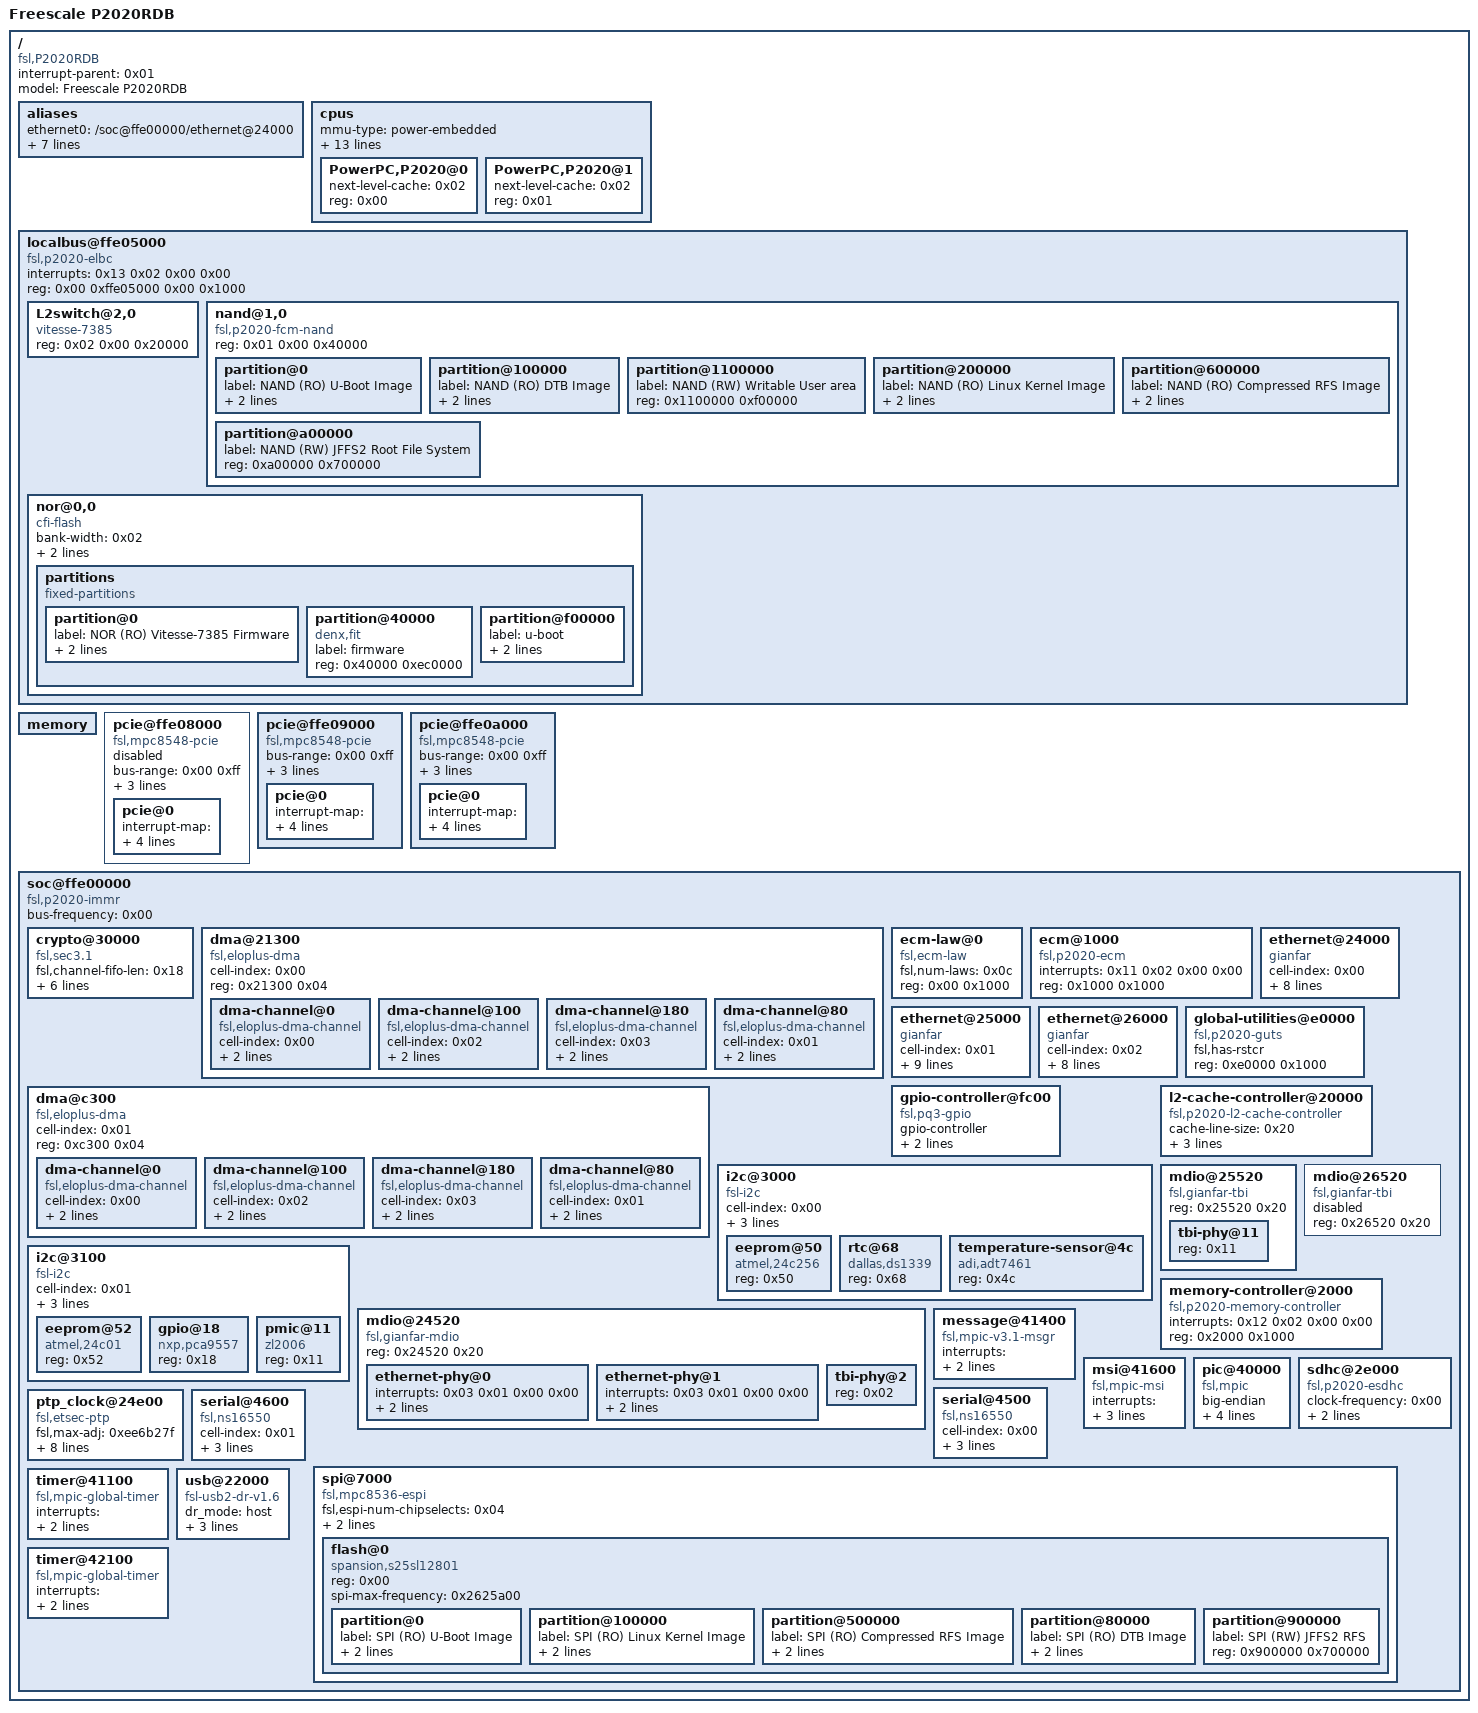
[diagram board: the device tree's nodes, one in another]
/dts-v1/;

/ {
	#address-cells = <0x02>;
	#size-cells = <0x02>;
	compatible = "fsl,P2020RDB";
	interrupt-parent = <0x01>;
	model = "Freescale P2020RDB";

	aliases {
		ethernet0 = "/soc@ffe00000/ethernet@24000";
		ethernet1 = "/soc@ffe00000/ethernet@25000";
		ethernet2 = "/soc@ffe00000/ethernet@26000";
		pci0 = "/pcie@ffe08000";
		pci1 = "/pcie@ffe09000";
		pci2 = "/pcie@ffe0a000";
		serial0 = "/soc@ffe00000/serial@4500";
		serial1 = "/soc@ffe00000/serial@4600";
	};

	cpus {
		#address-cells = <0x01>;
		#size-cells = <0x00>;
		mmu-type = "power-embedded";
		power-isa-atb;
		power-isa-b;
		power-isa-cs;
		power-isa-e;
		power-isa-e.le;
		power-isa-e.pm;
		power-isa-ecl;
		power-isa-mmc;
		power-isa-sp;
		power-isa-sp.fd;
		power-isa-sp.fs;
		power-isa-sp.fv;
		power-isa-version = "2.03";

		PowerPC,P2020@0 {
			device_type = "cpu";
			next-level-cache = <0x02>;
			reg = <0x00>;
		};

		PowerPC,P2020@1 {
			device_type = "cpu";
			next-level-cache = <0x02>;
			reg = <0x01>;
		};
	};

	localbus@ffe05000 {
		#address-cells = <0x02>;
		#size-cells = <0x01>;
		compatible = "fsl,p2020-elbc\0fsl,elbc\0simple-bus";
		interrupts = <0x13 0x02 0x00 0x00>;
		ranges = <0x00 0x00 0x00 0xef000000 0x1000000 0x01 0x00 0x00 0xffa00000 0x40000 0x02 0x00 0x00 0xffb00000 0x20000>;
		reg = <0x00 0xffe05000 0x00 0x1000>;

		L2switch@2,0 {
			#address-cells = <0x01>;
			#size-cells = <0x01>;
			compatible = "vitesse-7385";
			reg = <0x02 0x00 0x20000>;
		};

		nand@1,0 {
			#address-cells = <0x01>;
			#size-cells = <0x01>;
			compatible = "fsl,p2020-fcm-nand\0fsl,elbc-fcm-nand";
			reg = <0x01 0x00 0x40000>;

			partition@0 {
				label = "NAND (RO) U-Boot Image";
				read-only;
				reg = <0x00 0x100000>;
			};

			partition@100000 {
				label = "NAND (RO) DTB Image";
				read-only;
				reg = <0x100000 0x100000>;
			};

			partition@1100000 {
				label = "NAND (RW) Writable User area";
				reg = <0x1100000 0xf00000>;
			};

			partition@200000 {
				label = "NAND (RO) Linux Kernel Image";
				read-only;
				reg = <0x200000 0x400000>;
			};

			partition@600000 {
				label = "NAND (RO) Compressed RFS Image";
				read-only;
				reg = <0x600000 0x400000>;
			};

			partition@a00000 {
				label = "NAND (RW) JFFS2 Root File System";
				reg = <0xa00000 0x700000>;
			};
		};

		nor@0,0 {
			bank-width = <0x02>;
			compatible = "cfi-flash";
			device-width = <0x01>;
			reg = <0x00 0x00 0x1000000>;

			partitions {
				#address-cells = <0x01>;
				#size-cells = <0x01>;
				compatible = "fixed-partitions";

				partition@0 {
					label = "NOR (RO) Vitesse-7385 Firmware";
					read-only;
					reg = <0x00 0x40000>;
				};

				partition@40000 {
					compatible = "denx,fit";
					label = "firmware";
					reg = <0x40000 0xec0000>;
				};

				partition@f00000 {
					label = "u-boot";
					read-only;
					reg = <0xf00000 0x100000>;
				};
			};
		};
	};

	memory {
		device_type = "memory";
	};

	pcie@ffe08000 {
		#address-cells = <0x03>;
		#size-cells = <0x02>;
		bus-range = <0x00 0xff>;
		clock-frequency = <0x1fca055>;
		compatible = "fsl,mpc8548-pcie";
		device_type = "pci";
		interrupts = <0x1a 0x02 0x00 0x00>;
		reg = <0x00 0xffe08000 0x00 0x1000>;
		status = "disabled";

		pcie@0 {
			#address-cells = <0x03>;
			#interrupt-cells = <0x01>;
			#size-cells = <0x02>;
			device_type = "pci";
			interrupt-map = <0x00 0x00 0x00 0x01 0x01 0x00 0x01 0x00 0x00 0x00 0x00 0x00 0x02 0x01 0x01 0x01 0x00 0x00 0x00 0x00 0x00 0x03 0x01 0x02 0x01 0x00 0x00 0x00 0x00 0x00 0x04 0x01 0x03 0x01 0x00 0x00>;
			interrupt-map-mask = <0xf800 0x00 0x00 0x07>;
			interrupts = <0x1a 0x02 0x00 0x00>;
			reg = <0x00 0x00 0x00 0x00 0x00>;
		};
	};

	pcie@ffe09000 {
		#address-cells = <0x03>;
		#size-cells = <0x02>;
		bus-range = <0x00 0xff>;
		clock-frequency = <0x1fca055>;
		compatible = "fsl,mpc8548-pcie";
		device_type = "pci";
		interrupts = <0x19 0x02 0x00 0x00>;
		ranges = <0x2000000 0x00 0xa0000000 0x00 0xa0000000 0x00 0x20000000 0x1000000 0x00 0x00 0x00 0xffc10000 0x00 0x10000>;
		reg = <0x00 0xffe09000 0x00 0x1000>;

		pcie@0 {
			#address-cells = <0x03>;
			#interrupt-cells = <0x01>;
			#size-cells = <0x02>;
			device_type = "pci";
			interrupt-map = <0x00 0x00 0x00 0x01 0x01 0x04 0x01 0x00 0x00 0x00 0x00 0x00 0x02 0x01 0x05 0x01 0x00 0x00 0x00 0x00 0x00 0x03 0x01 0x06 0x01 0x00 0x00 0x00 0x00 0x00 0x04 0x01 0x07 0x01 0x00 0x00>;
			interrupt-map-mask = <0xf800 0x00 0x00 0x07>;
			interrupts = <0x19 0x02 0x00 0x00>;
			ranges = <0x2000000 0x00 0xa0000000 0x2000000 0x00 0xa0000000 0x00 0x20000000 0x1000000 0x00 0x00 0x1000000 0x00 0x00 0x00 0x100000>;
			reg = <0x00 0x00 0x00 0x00 0x00>;
		};
	};

	pcie@ffe0a000 {
		#address-cells = <0x03>;
		#size-cells = <0x02>;
		bus-range = <0x00 0xff>;
		clock-frequency = <0x1fca055>;
		compatible = "fsl,mpc8548-pcie";
		device_type = "pci";
		interrupts = <0x18 0x02 0x00 0x00>;
		ranges = <0x2000000 0x00 0x80000000 0x00 0x80000000 0x00 0x20000000 0x1000000 0x00 0x00 0x00 0xffc00000 0x00 0x10000>;
		reg = <0x00 0xffe0a000 0x00 0x1000>;

		pcie@0 {
			#address-cells = <0x03>;
			#interrupt-cells = <0x01>;
			#size-cells = <0x02>;
			device_type = "pci";
			interrupt-map = <0x00 0x00 0x00 0x01 0x01 0x08 0x01 0x00 0x00 0x00 0x00 0x00 0x02 0x01 0x09 0x01 0x00 0x00 0x00 0x00 0x00 0x03 0x01 0x0a 0x01 0x00 0x00 0x00 0x00 0x00 0x04 0x01 0x0b 0x01 0x00 0x00>;
			interrupt-map-mask = <0xf800 0x00 0x00 0x07>;
			interrupts = <0x18 0x02 0x00 0x00>;
			ranges = <0x2000000 0x00 0x80000000 0x2000000 0x00 0x80000000 0x00 0x20000000 0x1000000 0x00 0x00 0x1000000 0x00 0x00 0x00 0x100000>;
			reg = <0x00 0x00 0x00 0x00 0x00>;
		};
	};

	soc@ffe00000 {
		#address-cells = <0x01>;
		#size-cells = <0x01>;
		bus-frequency = <0x00>;
		compatible = "fsl,p2020-immr\0simple-bus";
		device_type = "soc";
		ranges = <0x00 0x00 0xffe00000 0x100000>;

		crypto@30000 {
			compatible = "fsl,sec3.1\0fsl,sec3.0\0fsl,sec2.4\0fsl,sec2.2\0fsl,sec2.1\0fsl,sec2.0";
			fsl,channel-fifo-len = <0x18>;
			fsl,descriptor-types-mask = <0x3ab0ebf>;
			fsl,exec-units-mask = <0xbfe>;
			fsl,num-channels = <0x04>;
			interrupts = <0x2d 0x02 0x00 0x00 0x3a 0x02 0x00 0x00>;
			reg = <0x30000 0x10000>;
		};

		dma@21300 {
			#address-cells = <0x01>;
			#size-cells = <0x01>;
			cell-index = <0x00>;
			compatible = "fsl,eloplus-dma";
			ranges = <0x00 0x21100 0x200>;
			reg = <0x21300 0x04>;

			dma-channel@0 {
				cell-index = <0x00>;
				compatible = "fsl,eloplus-dma-channel";
				interrupts = <0x14 0x02 0x00 0x00>;
				reg = <0x00 0x80>;
			};

			dma-channel@100 {
				cell-index = <0x02>;
				compatible = "fsl,eloplus-dma-channel";
				interrupts = <0x16 0x02 0x00 0x00>;
				reg = <0x100 0x80>;
			};

			dma-channel@180 {
				cell-index = <0x03>;
				compatible = "fsl,eloplus-dma-channel";
				interrupts = <0x17 0x02 0x00 0x00>;
				reg = <0x180 0x80>;
			};

			dma-channel@80 {
				cell-index = <0x01>;
				compatible = "fsl,eloplus-dma-channel";
				interrupts = <0x15 0x02 0x00 0x00>;
				reg = <0x80 0x80>;
			};
		};

		dma@c300 {
			#address-cells = <0x01>;
			#size-cells = <0x01>;
			cell-index = <0x01>;
			compatible = "fsl,eloplus-dma";
			ranges = <0x00 0xc100 0x200>;
			reg = <0xc300 0x04>;

			dma-channel@0 {
				cell-index = <0x00>;
				compatible = "fsl,eloplus-dma-channel";
				interrupts = <0x4c 0x02 0x00 0x00>;
				reg = <0x00 0x80>;
			};

			dma-channel@100 {
				cell-index = <0x02>;
				compatible = "fsl,eloplus-dma-channel";
				interrupts = <0x4e 0x02 0x00 0x00>;
				reg = <0x100 0x80>;
			};

			dma-channel@180 {
				cell-index = <0x03>;
				compatible = "fsl,eloplus-dma-channel";
				interrupts = <0x4f 0x02 0x00 0x00>;
				reg = <0x180 0x80>;
			};

			dma-channel@80 {
				cell-index = <0x01>;
				compatible = "fsl,eloplus-dma-channel";
				interrupts = <0x4d 0x02 0x00 0x00>;
				reg = <0x80 0x80>;
			};
		};

		ecm-law@0 {
			compatible = "fsl,ecm-law";
			fsl,num-laws = <0x0c>;
			reg = <0x00 0x1000>;
		};

		ecm@1000 {
			compatible = "fsl,p2020-ecm\0fsl,ecm";
			interrupts = <0x11 0x02 0x00 0x00>;
			reg = <0x1000 0x1000>;
		};

		ethernet@24000 {
			#address-cells = <0x01>;
			#size-cells = <0x01>;
			cell-index = <0x00>;
			compatible = "gianfar";
			device_type = "network";
			fixed-link = <0x01 0x01 0x3e8 0x00 0x00>;
			fsl,magic-packet;
			interrupts = <0x1d 0x02 0x00 0x00 0x1e 0x02 0x00 0x00 0x22 0x02 0x00 0x00>;
			local-mac-address = [00 00 00 00 00 00];
			model = "eTSEC";
			phy-connection-type = "rgmii-id";
			ranges = <0x00 0x24000 0x1000>;
			reg = <0x24000 0x1000>;
		};

		ethernet@25000 {
			#address-cells = <0x01>;
			#size-cells = <0x01>;
			cell-index = <0x01>;
			compatible = "gianfar";
			device_type = "network";
			fsl,magic-packet;
			interrupts = <0x23 0x02 0x00 0x00 0x24 0x02 0x00 0x00 0x28 0x02 0x00 0x00>;
			local-mac-address = [00 00 00 00 00 00];
			model = "eTSEC";
			phy-connection-type = "sgmii";
			phy-handle = <0x05>;
			ranges = <0x00 0x25000 0x1000>;
			reg = <0x25000 0x1000>;
			tbi-handle = <0x04>;
		};

		ethernet@26000 {
			#address-cells = <0x01>;
			#size-cells = <0x01>;
			cell-index = <0x02>;
			compatible = "gianfar";
			device_type = "network";
			fsl,magic-packet;
			interrupts = <0x1f 0x02 0x00 0x00 0x20 0x02 0x00 0x00 0x21 0x02 0x00 0x00>;
			local-mac-address = [00 00 00 00 00 00];
			model = "eTSEC";
			phy-connection-type = "rgmii-id";
			phy-handle = <0x06>;
			ranges = <0x00 0x26000 0x1000>;
			reg = <0x26000 0x1000>;
		};

		global-utilities@e0000 {
			compatible = "fsl,p2020-guts";
			fsl,has-rstcr;
			reg = <0xe0000 0x1000>;
		};

		gpio-controller@fc00 {
			#gpio-cells = <0x02>;
			compatible = "fsl,pq3-gpio";
			gpio-controller;
			interrupts = <0x2f 0x02 0x00 0x00>;
			phandle = <0x03>;
			reg = <0xfc00 0x100>;
		};

		i2c@3000 {
			#address-cells = <0x01>;
			#size-cells = <0x00>;
			cell-index = <0x00>;
			compatible = "fsl-i2c";
			dfsrr;
			interrupts = <0x2b 0x02 0x00 0x00>;
			reg = <0x3000 0x100>;

			eeprom@50 {
				compatible = "atmel,24c256";
				reg = <0x50>;
			};

			rtc@68 {
				compatible = "dallas,ds1339";
				reg = <0x68>;
			};

			temperature-sensor@4c {
				compatible = "adi,adt7461";
				reg = <0x4c>;
			};
		};

		i2c@3100 {
			#address-cells = <0x01>;
			#size-cells = <0x00>;
			cell-index = <0x01>;
			compatible = "fsl-i2c";
			dfsrr;
			interrupts = <0x2b 0x02 0x00 0x00>;
			reg = <0x3100 0x100>;

			eeprom@52 {
				compatible = "atmel,24c01";
				reg = <0x52>;
			};

			gpio@18 {
				compatible = "nxp,pca9557";
				reg = <0x18>;
			};

			pmic@11 {
				compatible = "zl2006";
				reg = <0x11>;
			};
		};

		l2-cache-controller@20000 {
			cache-line-size = <0x20>;
			cache-size = <0x80000>;
			compatible = "fsl,p2020-l2-cache-controller";
			interrupts = <0x10 0x02 0x00 0x00>;
			phandle = <0x02>;
			reg = <0x20000 0x1000>;
		};

		mdio@24520 {
			#address-cells = <0x01>;
			#size-cells = <0x00>;
			compatible = "fsl,gianfar-mdio";
			reg = <0x24520 0x20>;

			ethernet-phy@0 {
				interrupts = <0x03 0x01 0x00 0x00>;
				phandle = <0x05>;
				reg = <0x00>;
				reset-gpios = <0x03 0x0e 0x01>;
			};

			ethernet-phy@1 {
				interrupts = <0x03 0x01 0x00 0x00>;
				phandle = <0x06>;
				reg = <0x01>;
				reset-gpios = <0x03 0x06 0x01>;
			};

			tbi-phy@2 {
				device_type = "tbi-phy";
				reg = <0x02>;
			};
		};

		mdio@25520 {
			#address-cells = <0x01>;
			#size-cells = <0x00>;
			compatible = "fsl,gianfar-tbi";
			reg = <0x25520 0x20>;

			tbi-phy@11 {
				device_type = "tbi-phy";
				phandle = <0x04>;
				reg = <0x11>;
			};
		};

		mdio@26520 {
			#address-cells = <0x01>;
			#size-cells = <0x00>;
			compatible = "fsl,gianfar-tbi";
			reg = <0x26520 0x20>;
			status = "disabled";
		};

		memory-controller@2000 {
			compatible = "fsl,p2020-memory-controller";
			interrupts = <0x12 0x02 0x00 0x00>;
			reg = <0x2000 0x1000>;
		};

		message@41400 {
			compatible = "fsl,mpic-v3.1-msgr";
			interrupts = <0xb0 0x02 0x00 0x00 0xb1 0x02 0x00 0x00 0xb2 0x02 0x00 0x00 0xb3 0x02 0x00 0x00>;
			reg = <0x41400 0x200>;
		};

		msi@41600 {
			compatible = "fsl,mpic-msi";
			interrupts = <0xe0 0x00 0x00 0x00 0xe1 0x00 0x00 0x00 0xe2 0x00 0x00 0x00 0xe3 0x00 0x00 0x00 0xe4 0x00 0x00 0x00 0xe5 0x00 0x00 0x00 0xe6 0x00 0x00 0x00 0xe7 0x00 0x00 0x00>;
			msi-available-ranges = <0x00 0x100>;
			reg = <0x41600 0x80>;
		};

		pic@40000 {
			#address-cells = <0x00>;
			#interrupt-cells = <0x04>;
			big-endian;
			compatible = "fsl,mpic";
			device_type = "open-pic";
			interrupt-controller;
			last-interrupt-source = <0xff>;
			phandle = <0x01>;
			reg = <0x40000 0x40000>;
			single-cpu-affinity;
		};

		ptp_clock@24e00 {
			compatible = "fsl,etsec-ptp";
			fsl,max-adj = <0xee6b27f>;
			fsl,tclk-period = <0x05>;
			fsl,tmr-add = <0xcccccccd>;
			fsl,tmr-fiper1 = <0x3b9ac9fb>;
			fsl,tmr-fiper2 = <0x1869b>;
			fsl,tmr-prsc = <0xc8>;
			interrupts = <0x44 0x02 0x00 0x00 0x45 0x02 0x00 0x00 0x46 0x02 0x00 0x00>;
			reg = <0x24e00 0xb0>;
		};

		sdhc@2e000 {
			clock-frequency = <0x00>;
			compatible = "fsl,p2020-esdhc\0fsl,esdhc";
			interrupts = <0x48 0x02 0x00 0x00>;
			reg = <0x2e000 0x1000>;
		};

		serial@4500 {
			cell-index = <0x00>;
			clock-frequency = <0x00>;
			compatible = "fsl,ns16550\0ns16550";
			device_type = "serial";
			interrupts = <0x2a 0x02 0x00 0x00>;
			reg = <0x4500 0x100>;
		};

		serial@4600 {
			cell-index = <0x01>;
			clock-frequency = <0x00>;
			compatible = "fsl,ns16550\0ns16550";
			device_type = "serial";
			interrupts = <0x2a 0x02 0x00 0x00>;
			reg = <0x4600 0x100>;
		};

		spi@7000 {
			#address-cells = <0x01>;
			#size-cells = <0x00>;
			compatible = "fsl,mpc8536-espi";
			fsl,espi-num-chipselects = <0x04>;
			interrupts = <0x3b 0x02 0x00 0x00>;
			reg = <0x7000 0x1000>;

			flash@0 {
				#address-cells = <0x01>;
				#size-cells = <0x01>;
				compatible = "spansion,s25sl12801\0jedec,spi-nor";
				reg = <0x00>;
				spi-max-frequency = <0x2625a00>;

				partition@0 {
					label = "SPI (RO) U-Boot Image";
					read-only;
					reg = <0x00 0x80000>;
				};

				partition@100000 {
					label = "SPI (RO) Linux Kernel Image";
					read-only;
					reg = <0x100000 0x400000>;
				};

				partition@500000 {
					label = "SPI (RO) Compressed RFS Image";
					read-only;
					reg = <0x500000 0x400000>;
				};

				partition@80000 {
					label = "SPI (RO) DTB Image";
					read-only;
					reg = <0x80000 0x80000>;
				};

				partition@900000 {
					label = "SPI (RW) JFFS2 RFS";
					reg = <0x900000 0x700000>;
				};
			};
		};

		timer@41100 {
			compatible = "fsl,mpic-global-timer";
			interrupts = <0x00 0x00 0x03 0x00 0x01 0x00 0x03 0x00 0x02 0x00 0x03 0x00 0x03 0x00 0x03 0x00>;
			reg = <0x41100 0x100 0x41300 0x04>;
		};

		timer@42100 {
			compatible = "fsl,mpic-global-timer";
			interrupts = <0x04 0x00 0x03 0x00 0x05 0x00 0x03 0x00 0x06 0x00 0x03 0x00 0x07 0x00 0x03 0x00>;
			reg = <0x42100 0x100 0x42300 0x04>;
		};

		usb@22000 {
			#address-cells = <0x01>;
			#size-cells = <0x00>;
			compatible = "fsl-usb2-dr-v1.6\0fsl-usb2-dr";
			dr_mode = "host";
			interrupts = <0x1c 0x02 0x00 0x00>;
			phy_type = "ulpi";
			reg = <0x22000 0x1000>;
		};
	};
};
